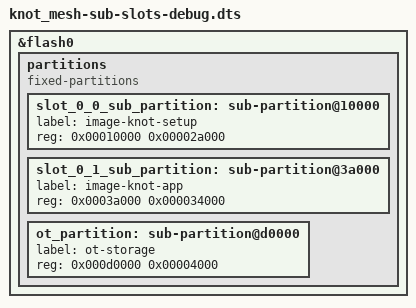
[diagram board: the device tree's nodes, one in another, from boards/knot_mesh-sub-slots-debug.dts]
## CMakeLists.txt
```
cmake_minimum_required(VERSION 3.8.2)
find_package(Git REQUIRED)

set(CONF_FILE
        "$ENV{KNOT_BASE}/core/core.conf \
         $ENV{KNOT_BASE}/core/overlay-knot-ot.conf \
         $ENV{KNOT_BASE}/core/boards/${BOARD}.conf \
         prj.conf"
)

if(NOT BOARD)
        error("Board not defined!")
endif ()

set(KCONFIG_ROOT $ENV{KNOT_BASE}/core/Kconfig)

if (NOT ${BOARD} STREQUAL qemu_x86)
        # Change dts with sub-partitions and use specific sub-partition to flash
        # Use special dts overlay in case of debugging
        if (KNOT_DEBUG)
                set(DTC_OVERLAY_MULTI_SLOT
                        $ENV{KNOT_BASE}/core/boards/${BOARD}-sub-slots-debug.dts
                )
        else()
                set(DTC_OVERLAY_MULTI_SLOT
                        $ENV{KNOT_BASE}/core/boards/${BOARD}-sub-slots-stock.dts
                )
        endif()
        set(DTC_OVERLAY_SET_SLOT
                $ENV{KNOT_BASE}/core/boards/overlay-main.dts
        )
        set(DTC_OVERLAY_FILE
                "${DTC_OVERLAY_FILE} ${DTC_OVERLAY_MULTI_SLOT} \
                 ${DTC_OVERLAY_SET_SLOT} ${DTC_OVERLAY_USER}"
        )
endif ()

include($ENV{ZEPHYR_BASE}/cmake/app/boilerplate.cmake NO_POLICY_SCOPE)

include(ExternalProject)

zephyr_get_include_directories_for_lang_as_string(C includes)
zephyr_get_system_include_directories_for_lang_as_string(C system_includes)
zephyr_get_compile_options_for_lang_as_string(C c_options)

set(PROTO_ROOT ${CMAKE_CURRENT_LIST_DIR}/build/external/proto)
set(PROTO_LIB_DIR ${PROTO_ROOT}/lib)
set(PROTO_INCLUDE_DIR ${PROTO_ROOT}/include)
set(PROTO_LIB knotprotocol)
if(EXTERNAL_PROJECT_PATH_KNOT_PROTOCOL)
        set(PROTO_SOURCE ${EXTERNAL_PROJECT_PATH_KNOT_PROTOCOL})
else()
        set(PROTO_GIT_REPO https://github.com/CESARBR/knot-protocol-source.git)
        set(PROTO_SOURCE ${PROTO_ROOT}/src/proto)
endif()

set(configure_flags
  "CC=${CMAKE_C_COMPILER}"
  "RANLIB=${CMAKE_RANLIB}"
  "CFLAGS=${c_options} ${includes} ${system_includes}"
  "LDFLAGS=-nostdlib"# Don't use the standard system startup files or libraries
  --host=${CROSS_COMPILE_TARGET}
  --target=${CROSS_COMPILE_TARGET}
  --prefix=${PROTO_ROOT}
)

add_library(${PROTO_LIB} STATIC IMPORTED GLOBAL)

set_target_properties(${PROTO_LIB} PROPERTIES IMPORTED_LOCATION
    ${PROTO_LIB_DIR}/lib${PROTO_LIB}.a
)

target_include_directories(app SYSTEM PRIVATE ${PROTO_INCLUDE_DIR})

target_link_libraries(app INTERFACE ${PROTO_LIB})

ExternalProject_Add(proto
    PREFIX ${PROTO_ROOT}
    BINARY_DIR ${PROTO_SOURCE}
    SOURCE_DIR ${PROTO_SOURCE}
    GIT_REPOSITORY ${PROTO_GIT_REPO}
    BUILD_BYPRODUCTS ${PROTO_LIB_DIR}/lib${PROTO_LIB}.a
    CONFIGURE_COMMAND ./bootstrap && ./configure ${configure_flags}

    COMMENT "bootstrapping..." # Text printed when step executes
    BUILD_COMMAND make
)

add_dependencies(proto syscall_list_h_target)
add_dependencies(proto syscall_macros_h_target)

add_dependencies(app proto)
if (NOT ${BOARD} STREQUAL qemu_x86)
        add_dependencies(app ot)
endif ()

FILE(GLOB core_sources $ENV{KNOT_BASE}/core/src/*.c)
target_sources(app PRIVATE ${core_sources})
target_include_directories(app PRIVATE $ENV{KNOT_BASE}/core/src)
```

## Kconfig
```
mainmenu "KNoT sample application"

menu "KNoT Thing"

config KNOT_NAME
	string "KNoT device name"
	default "knot"

config KNOT_THING_DATA_MAX
	int "Max number of KNoT items (sensors)"
	default 3

config KNOT_LOG
	bool "Enable KNoT log"
	default n
	help
	  This option enables log support for KNoT
	depends on LOG

choice
	prompt "KNoT log level"
	depends on KNOT_LOG
	help
	  This option selects KNoT log level.

config KNOT_LOG_LEVEL_ERROR
	bool "Error"
config KNOT_LOG_LEVEL_WARNING
	bool "Warning"
config KNOT_LOG_LEVEL_INFO
	bool "Info"
config KNOT_LOG_LEVEL_DEBUG
	bool "Debug"

endchoice

config KNOT_LOG_LEVEL
	int
	default 0 if !KNOT_LOG
	default 1 if KNOT_LOG_LEVEL_ERROR
	default 2 if KNOT_LOG_LEVEL_WARNING
	default 3 if KNOT_LOG_LEVEL_INFO
	default 4 if KNOT_LOG_LEVEL_DEBUG

endmenu

source "Kconfig.zephyr"
```

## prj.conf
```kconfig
# Generic networking options
CONFIG_NETWORKING=y
CONFIG_NET_TCP=y
CONFIG_NET_IPV6=y

# Kernel options
CONFIG_INIT_STACKS=y

# Logging
CONFIG_LOG=y
CONFIG_LOG_INPLACE_PROCESS=y


# Threading
CONFIG_NUM_PIPE_ASYNC_MSGS=2

# Network application options and configuration
CONFIG_NET_APP=y
CONFIG_NET_APP_CLIENT=y
CONFIG_NET_CONFIG_AUTO_INIT=y

CONFIG_NET_CONFIG_SETTINGS=y
CONFIG_NET_CONFIG_NEED_IPV6=y
CONFIG_NET_CONFIG_MY_IPV6_ADDR="2001:db8::1"
CONFIG_NET_CONFIG_PEER_IPV6_ADDR="2001:db8::2"
```

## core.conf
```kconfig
# Generic networking options
CONFIG_NETWORKING=y
CONFIG_NET_TCP=y
CONFIG_NET_UDP=n
CONFIG_NET_IPV6=y

# Kernel options
CONFIG_INIT_STACKS=y

# Threading
CONFIG_NUM_PIPE_ASYNC_MSGS=2

# Network application options and configuration
CONFIG_NET_SOCKETS=y
CONFIG_NET_CONFIG_AUTO_INIT=y

CONFIG_NET_CONFIG_SETTINGS=y
CONFIG_NET_CONFIG_NEED_IPV6=y
CONFIG_NET_CONFIG_MY_IPV6_ADDR="2001:db8::1"
CONFIG_NET_CONFIG_PEER_IPV6_ADDR="2001:db8::2"
```

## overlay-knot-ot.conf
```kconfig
CONFIG_CPLUSPLUS=y

# Disable IPv4
CONFIG_NET_IPV4=n

CONFIG_NET_IPV6=y
CONFIG_NET_IPV6_NBR_CACHE=n
CONFIG_NET_IPV6_MLD=n
CONFIG_NET_CONFIG_NEED_IPV6=y
CONFIG_NET_CONFIG_NEED_IPV4=n
CONFIG_NET_CONFIG_MY_IPV4_ADDR=""
CONFIG_NET_CONFIG_PEER_IPV4_ADDR=""

CONFIG_MAIN_STACK_SIZE=2048
CONFIG_SYSTEM_WORKQUEUE_STACK_SIZE=2048
CONFIG_NET_TX_STACK_SIZE=2048
CONFIG_NET_RX_STACK_SIZE=5120

# Disable conflicting IEEE802154 L2
CONFIG_NET_L2_IEEE802154=n
CONFIG_NET_L2_IEEE802154_SHELL=n
CONFIG_NET_DEBUG_L2_IEEE802154_FRAGMENT=n

CONFIG_NET_L2_OPENTHREAD=y

CONFIG_OPENTHREAD_DEBUG=y
CONFIG_OPENTHREAD_L2_DEBUG=y

# Openthread connection parameters
# Define invalid parameters to avoid starting a Thread network at system startup
CONFIG_OPENTHREAD_CHANNEL=0
CONFIG_OPENTHREAD_PANID=65535
CONFIG_OPENTHREAD_NETWORK_NAME=""
CONFIG_OPENTHREAD_XPANID=""
CONFIG_OPENTHREAD_MTD=y

# Thread by default registers quite a lot addresses.
CONFIG_NET_IF_UNICAST_IPV6_ADDR_COUNT=6
CONFIG_NET_IF_MCAST_IPV6_ADDR_COUNT=8

# Get OpenThread Settings from storage
CONFIG_SETTINGS_OT=y

# Set number of flash pages to be used by OpenThread
# It should be limited by the OT_STORAGE flash sub-partition size
CONFIG_OT_PLAT_FLASH_PAGES_COUNT=4
```

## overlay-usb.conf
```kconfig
# Enable shell without input options
CONFIG_SHELL=y
CONFIG_LOG_CMDS=n
CONFIG_SHELL_BACKSPACE_MODE_DELETE=n
CONFIG_SHELL_WILDCARD=n
CONFIG_SHELL_ECHO_STATUS=n
CONFIG_SHELL_METAKEYS=n
CONFIG_SHELL_HELP=n
CONFIG_SHELL_HELP_ON_WRONG_ARGUMENT_COUNT=n
CONFIG_SHELL_HISTORY=n
CONFIG_SHELL_STATS=n
CONFIG_SHELL_CMDS=n
CONFIG_SHELL_CMDS_RESIZE=n

# Enable UART Interruptions
CONFIG_UART_INTERRUPT_DRIVEN=y
CONFIG_UART_0_NRF_UARTE=y
CONFIG_UART_0_INTERRUPT_DRIVEN=y

# USB Stack
CONFIG_USB=y
CONFIG_USB_DEVICE_STACK=y
CONFIG_USB_CDC_ACM=y
CONFIG_USB_UART_CONSOLE=y
CONFIG_USB_MASS_STORAGE=n
CONFIG_USB_DEVICE_PRODUCT="KNoT Thing"

# Use LOG for printk messages
CONFIG_LOG_PRINTK=y

# Use console and shell for output
CONFIG_CONSOLE=y
CONFIG_STDOUT_CONSOLE=y
CONFIG_UART_SHELL_ON_DEV_NAME="CDC_ACM_0"
CONFIG_UART_CONSOLE=y
CONFIG_SERIAL=y
```

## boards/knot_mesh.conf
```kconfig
CONFIG_BT=n
CONFIG_BT_CTLR=n

CONFIG_GPIO=y

CONFIG_NET_TX_STACK_SIZE=4096
CONFIG_NET_RX_STACK_SIZE=5120

CONFIG_REBOOT=y

CONFIG_FLASH=y
CONFIG_FLASH_PAGE_LAYOUT=y
CONFIG_MPU_ALLOW_FLASH_WRITE=y

CONFIG_NET_TCP=y

CONFIG_IEEE802154_NRF5=y
CONFIG_IEEE802154_NRF5_DRV_NAME="IEEE802154_nrf5"
CONFIG_IEEE802154_NRF5_INIT_PRIO=80

CONFIG_TEST_RANDOM_GENERATOR=n
CONFIG_ENTROPY_NRF5_RNG=y

CONFIG_SYS_CLOCK_TICKS_PER_SEC=1000

CONFIG_FLOAT=y
CONFIG_FP_SHARING=y

# Flash kernel at choosen code partition
CONFIG_USE_CODE_PARTITION=y


# Settings
CONFIG_FLASH_MAP=y
CONFIG_SETTINGS=y
CONFIG_FCB=y
CONFIG_SETTINGS_FCB=y
CONFIG_SETTINGS_FCB_NUM_AREAS=4

# Disable UART to avoid conflicts with OpenThread
CONFIG_OPENTHREAD_SHELL=y
CONFIG_SHELL=y

# Disable shell inputs to better performance
CONFIG_LOG_CMDS=n
CONFIG_SHELL_BACKSPACE_MODE_DELETE=n
CONFIG_SHELL_WILDCARD=n
CONFIG_SHELL_ECHO_STATUS=n
CONFIG_SHELL_METAKEYS=n
CONFIG_SHELL_HELP=n
CONFIG_SHELL_HELP_ON_WRONG_ARGUMENT_COUNT=n
CONFIG_SHELL_HISTORY=n
CONFIG_SHELL_STATS=n
CONFIG_SHELL_CMDS=n
CONFIG_SHELL_CMDS_RESIZE=n

# Network buffers
CONFIG_NET_PKT_RX_COUNT=16
CONFIG_NET_PKT_TX_COUNT=16
CONFIG_NET_BUF_RX_COUNT=80
CONFIG_NET_BUF_TX_COUNT=80

# IP address options
CONFIG_NET_MAX_CONTEXTS=10

# USB
CONFIG_USB=y
CONFIG_USB_DEVICE_STACK=y
CONFIG_USB_CDC_ACM=y
CONFIG_USB_DEVICE_PRODUCT="KNoT Thing"
CONFIG_UART_SHELL_ON_DEV_NAME="CDC_ACM_0"
```

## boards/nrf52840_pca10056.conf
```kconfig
CONFIG_BT=n
CONFIG_BT_CTLR=n

CONFIG_GPIO=y

CONFIG_NET_TX_STACK_SIZE=4096
CONFIG_NET_RX_STACK_SIZE=5120

CONFIG_REBOOT=y

CONFIG_FLASH=y
CONFIG_FLASH_PAGE_LAYOUT=y
CONFIG_MPU_ALLOW_FLASH_WRITE=y

CONFIG_NET_TCP=y

CONFIG_IEEE802154_NRF5=y
CONFIG_IEEE802154_NRF5_DRV_NAME="IEEE802154_nrf5"
CONFIG_IEEE802154_NRF5_INIT_PRIO=80

CONFIG_TEST_RANDOM_GENERATOR=n
CONFIG_ENTROPY_NRF5_RNG=y

CONFIG_SYS_CLOCK_TICKS_PER_SEC=1000

CONFIG_FLOAT=y
CONFIG_FP_SHARING=y

# Flash kernel at choosen code partition
CONFIG_USE_CODE_PARTITION=y

# Settings
CONFIG_FLASH_MAP=y
CONFIG_SETTINGS=y
CONFIG_FCB=y
CONFIG_SETTINGS_FCB=y
CONFIG_SETTINGS_FCB_NUM_AREAS=8

# Shell
CONFIG_OPENTHREAD_SHELL=n
CONFIG_SHELL=n

# Network buffers
CONFIG_NET_PKT_RX_COUNT=16
CONFIG_NET_PKT_TX_COUNT=16
CONFIG_NET_BUF_RX_COUNT=80
CONFIG_NET_BUF_TX_COUNT=80

# IP address options
CONFIG_NET_MAX_CONTEXTS=10
```

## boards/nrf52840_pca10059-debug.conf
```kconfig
# Logging
CONFIG_LOG=y
CONFIG_LOG_PRINTK=y
CONFIG_LOG_IMMEDIATE=n

CONFIG_KNOT_LOG=y
CONFIG_KNOT_LOG_LEVEL_DEBUG=y

# USB
CONFIG_USB=y
CONFIG_USB_DEVICE_STACK=y
CONFIG_USB_CDC_ACM=y
CONFIG_USB_UART_CONSOLE=y
CONFIG_USB_DEVICE_PRODUCT="KNoT Thing"
CONFIG_USB_MASS_STORAGE=n

# Use console and shell for output
CONFIG_CONSOLE=y
CONFIG_STDOUT_CONSOLE=y

CONFIG_UART_CONSOLE=y
CONFIG_UART_SHELL_ON_DEV_NAME="CDC_ACM_0"

CONFIG_SERIAL=y

# Disable shell input options
CONFIG_LOG_CMDS=n
CONFIG_SHELL=y
CONFIG_SHELL_BACKSPACE_MODE_DELETE=n
CONFIG_SHELL_WILDCARD=n
CONFIG_SHELL_ECHO_STATUS=n
CONFIG_SHELL_METAKEYS=n
CONFIG_SHELL_HELP=n
CONFIG_SHELL_HELP_ON_WRONG_ARGUMENT_COUNT=n
CONFIG_SHELL_HISTORY=n
CONFIG_SHELL_STATS=n
CONFIG_SHELL_CMDS=n
CONFIG_SHELL_CMDS_RESIZE=n
CONFIG_SHELL_BACKEND_SERIAL_INTERRUPT_DRIVEN=n
```

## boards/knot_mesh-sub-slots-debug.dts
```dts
/*
 * Overlay file to permit using sub-slots with extend space for setup app.
 * This file is meant for apps on debug mode, not stock mode.
 */
&flash0 {
	/*
	 * For more information, see:
	 * http://docs.zephyrproject.org/latest/devices/dts/flash_partitions.html
	 */
	partitions {
		compatible = "fixed-partitions";
		#address-cells = <1>;
		#size-cells = <1>;

		/*
		 * Hack: Split image-0 into two sub-images
		 * (knot-setup and knot-app) so they can be refer to each other
		 * and recognized by MCUBOOT as a single image.
		 */

		slot_0_0_sub_partition: sub-partition@10000 {
			label = "image-knot-setup";
			reg = <0x00010000 0x00002a000>;
		};

		slot_0_1_sub_partition: sub-partition@3a000 {
			label = "image-knot-app";
			reg = <0x0003a000 0x000034000>;
		};

		/*
		 * Using first 4 pages of scratch partition for
		 * OpenThread storage.
		 * This is allowed as the scratch area is used only
		 * during OTA update.
		 */
		ot_partition: sub-partition@d0000 {
			label = "ot-storage";
			reg = <0x000d0000 0x00004000>;
		};
	};
};
```

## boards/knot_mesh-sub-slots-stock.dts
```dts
/*
 * Overlay file to permit using sub-slots with reduced space for setup app.
 */
&flash0 {
	/*
	 * For more information, see:
	 * http://docs.zephyrproject.org/latest/devices/dts/flash_partitions.html
	 */
	partitions {
		compatible = "fixed-partitions";
		#address-cells = <1>;
		#size-cells = <1>;

		/*
		 * Hack: Split image-0 into two sub-images
		 * (knot-setup and knot-app) so they can be refer to each other
		 * and recognized by MCUBOOT as a single image.
		 */

		slot_0_0_sub_partition: sub-partition@10000 {
			label = "image-knot-setup";
			reg = <0x00010000 0x00001c000>;
		};

		slot_0_1_sub_partition: sub-partition@2c000 {
			label = "image-knot-app";
			reg = <0x0002c000 0x000042000>;
		};

		/*
		 * Using first 4 pages of scratch partition for
		 * OpenThread storage.
		 * This is allowed as scratch area is used only
		 * during OTA update.
		 */
		ot_partition: sub-partition@d0000 {
			label = "ot-storage";
			reg = <0x000d0000 0x00004000>;
		};
		/* Nordic nRF5 bootloader <0xe0000 0x1c000>
		 *
		 * In addition, the last and second last flash pages
		 * are used by the nRF5 bootloader and MBR to store settings.
		 */
	};
};
```

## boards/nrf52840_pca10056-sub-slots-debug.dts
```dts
/*
 * Overlay file to permit using sub-slots with extend space for setup app.
 * This file is meant for apps on debug mode, not stock mode.
 */
&flash0 {
	/*
	 * For more information, see:
	 * http://docs.zephyrproject.org/latest/devices/dts/flash_partitions.html
	 */
	partitions {
		compatible = "fixed-partitions";
		#address-cells = <1>;
		#size-cells = <1>;

		/*
		 * Hack: Split image-0 into two sub-images
		 * (knot-setup and knot-app) so they can be refer to each other
		 * and recognized by MCUBOOT as a single image.
		 */

		slot_0_0_sub_partition: sub-partition@c000 {
			label = "image-knot-setup";
			reg = <0x0000C000 0x000030000>;
		};

		slot_0_1_sub_partition: sub-partition@3c000 {
			label = "image-knot-app";
			reg = <0x0003C000 0x000037000>;
		};

		/*
		 * Using last 4 pages of storage partition
		 */

		ot_partition: partition@fe000 {
			label = "ot-storage";
			reg = <0x000fc000 0x00004000>;
		};
	};
};
```

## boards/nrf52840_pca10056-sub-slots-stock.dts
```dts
/*
 * Overlay file to permit using sub-slots with reduced space for setup app.
 */
&flash0 {
	/*
	 * For more information, see:
	 * http://docs.zephyrproject.org/latest/devices/dts/flash_partitions.html
	 */
	partitions {
		compatible = "fixed-partitions";
		#address-cells = <1>;
		#size-cells = <1>;

		/*
		 * Hack: Split image-0 into two sub-images
		 * (knot-setup and knot-app) so they can be refer to each other
		 * and recognized by MCUBOOT as a single image.
		 */

		slot_0_0_sub_partition: sub-partition@c000 {
			label = "image-knot-setup";
			reg = <0x0000c000 0x00001c000>;
		};

		slot_0_1_sub_partition: sub-partition@28000 {
			label = "image-knot-app";
			reg = <0x00028000 0x00004b000>;
		};

		/*
		 * Using first 4 pages of scratch partition for
		 * OpenThread storage.
		 * This is allowed as scratch area is used only
		 * during OTA update.
		 */
		ot_partition: sub-partition@da000 {
			label = "ot-storage";
			reg = <0x000da000 0x00004000>;
		};
	};
};
```

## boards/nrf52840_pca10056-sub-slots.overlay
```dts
&flash0 {
	/*
	 * For more information, see:
	 * http://docs.zephyrproject.org/latest/devices/dts/flash_partitions.html
	 */
	partitions {
		compatible = "fixed-partitions";
		#address-cells = <1>;
		#size-cells = <1>;

		/*
		 * Hack: Split image-0 into two sub-images
		 * (knot-setup and knot-app) so they can be refer to each other
		 * and recognized by MCUBOOT as a single image.
		 */

		slot_0_0_sub_partition: sub-partition@c000 {
			label = "image-knot-setup";
			reg = <0x0000C000 0x000020000>;
		};

		slot_0_1_sub_partition: sub-partition@2c000 {
			label = "image-knot-app";
			reg = <0x0002C000 0x000047000>;
		};

		/*
		 * Using last 4 pages of storage partition
		 */

		ot_partition: partition@fe000 {
			label = "ot-storage";
			reg = <0x000fc000 0x00004000>;
		};
	};
};
```

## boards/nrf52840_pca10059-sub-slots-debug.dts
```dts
/*
 * Overlay file to permit using sub-slots with extend space for setup app.
 * This file is meant for apps on debug mode, not stock mode.
 */
&flash0 {
	/*
	 * For more information, see:
	 * http://docs.zephyrproject.org/latest/devices/dts/flash_partitions.html
	 */
	partitions {
		compatible = "fixed-partitions";
		#address-cells = <1>;
		#size-cells = <1>;

		/*
		 * Hack: Split image-0 into two sub-images
		 * (knot-setup and knot-app) so they can be refer to each other
		 * and recognized by MCUBOOT as a single image.
		 */

		slot_0_0_sub_partition: sub-partition@10000 {
			label = "image-knot-setup";
			reg = <0x00010000 0x00002a000>;
		};

		slot_0_1_sub_partition: sub-partition@3a000 {
			label = "image-knot-app";
			reg = <0x0003a000 0x000034000>;
		};

		/*
		 * Using last 2 pages of storage partition
		 */
		ot_partition: partition@fe000 {
			label = "ot-storage";
			reg = <0x000ce000 0x00002000>;
		};
	};
};
```

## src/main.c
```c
/* main.c - KNoT Application Client */

/*
 * Copyright (c) 2018, CESAR. All rights reserved.
 *
 * SPDX-License-Identifier: Apache-2.0
 */

/*
 * The knot client application is acting as a client that is run in Zephyr OS,
 * The client sends sensor data encapsulated using KNoT protocol.
 */

#include <zephyr.h>
#include <net/net_core.h>
#include <logging/log.h>
#include <settings/settings.h>
#if CONFIG_SETTINGS_OT
	#include <settings/settings_ot.h>
#endif

#include "proto.h"
#include "net.h"
#include "storage.h"

LOG_MODULE_REGISTER(knot, CONFIG_KNOT_LOG_LEVEL);
K_PIPE_DEFINE(p2n_pipe, 128, 4);
K_PIPE_DEFINE(n2p_pipe, 128, 4);
static struct k_sem quit_lock;

void main(void)
{
	int ret;

	LOG_DBG("*** Welcome to KNoT! %s\n", CONFIG_ARCH);

	k_sem_init(&quit_lock, 0, UINT_MAX);

	/* Guarantees NET and PROTO threads will be created */
	k_sched_lock();

	/* Initializing KNoT storage */
	LOG_DBG("Initializing storage module");
	ret = storage_init();
	if (ret)
		LOG_ERR("KNoT Storage init failed!");

	#if CONFIG_SETTINGS_OT
		/* Initializing OpenThread settings */
		LOG_DBG("Initializing OpenThread settings");
		ret = settings_ot_init();
		if (ret)
			LOG_ERR("OpenThread settings init failed!");

	#endif

	#if CONFIG_SETTINGS
		LOG_DBG("Loading stored values");
		ret = settings_load();
		if (ret)
			LOG_ERR("Settings load failed (err %d)", ret);
	#endif

	/*
	 * KNoT state thread: manage device registration, detects
	 * sensor data changes acting like a proxy forwarding data
	 * from sensors to network layer (and oposite). Proto is
	 * consumer of ipdu fifo and producer of opdu.
	 */
	if (proto_start(&p2n_pipe, &n2p_pipe) < 0)
		return;

	/*
	 * Network thread: manage traffic from TCP or non-ip wireless
	 * technologies. Each technology(thread) is responsible for
	 * managing incoming and outgoing data. Net is consumer of
	 * opdu fifo and producer of ipdu.
	 */
	if (net_start(&p2n_pipe, &n2p_pipe) < 0)
		return;

	/* Allows NET and PROTO thread scheduling */
	k_sched_unlock();

	k_sem_take(&quit_lock, K_FOREVER);

	net_stop();
	proto_stop();
}
```

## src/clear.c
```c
/*
 * Copyright (c) 2019, CESAR. All rights reserved.
 *
 * SPDX-License-Identifier: Apache-2.0
 */

#if !CONFIG_BOARD_QEMU_X86
#include <zephyr.h>
#include <settings/settings_ot.h>
#include <logging/log.h>
#include <flash.h>

#include "storage.h"
#include "clear.h"

LOG_MODULE_REGISTER(knot_clear, CONFIG_KNOT_LOG_LEVEL);

int clear_ot_nvs(void)
{
	struct device *flash_dev;
	int rc;

	flash_dev = device_get_binding(DT_FLASH_DEV_NAME);
	if (!flash_dev) {
		LOG_ERR("Flash driver was not found!");
		return -1;
	}

	/* Erase OpenThread flash partition */
	flash_write_protection_set(flash_dev, false);
	rc = flash_erase(flash_dev,
			 DT_FLASH_AREA_OT_STORAGE_OFFSET,
			 DT_FLASH_AREA_OT_STORAGE_SIZE);
	if (rc)
		LOG_ERR("Failed to clear OpenThread's NVS");

	flash_write_protection_set(flash_dev, true);

	return rc;
}

static int clear_settings(void)
{
	struct device *flash_dev;
	int rc;

	flash_dev = device_get_binding(DT_FLASH_DEV_NAME);
	if (!flash_dev) {
		LOG_ERR("Flash driver was not found!");
		return -1;
	}

	/* Erase Storage flash partition */
	flash_write_protection_set(flash_dev, false);
	rc = flash_erase(flash_dev,
			 DT_FLASH_AREA_STORAGE_OFFSET,
			 DT_FLASH_AREA_STORAGE_SIZE);
	if (rc)
		LOG_ERR("Failed to clear Storage flash partition");

	flash_write_protection_set(flash_dev, true);

	return rc;
}

int clear_factory(void)
{
	int rc;
	int ret = 0;

	rc = storage_reset();
	if (rc)
		ret = -1;

	rc = settings_ot_reset();
	if (rc)
		ret = -1;

	rc = clear_ot_nvs();
	if (rc)
		ret = -1;

	rc = clear_settings();
	if (rc)
		ret = -1;

	return ret;
}
#endif
```

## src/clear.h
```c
/*
 * Copyright (c) 2019, CESAR. All rights reserved.
 *
 * SPDX-License-Identifier: Apache-2.0
 */

int clear_ot_nvs(void);

int clear_factory(void);
```

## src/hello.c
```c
/* net.c - KNoT Application Client */

/*
 * Copyright (c) 2018, CESAR. All rights reserved.
 *
 * SPDX-License-Identifier: Apache-2.0
 */

/*
 * The knot client application is acting as a client that is run in Zephyr OS,
 * The client sends sensor data encapsulated using KNoT netcol.
 */


#include <zephyr.h>
#include <net/net_core.h>
#include <logging/log.h>

#include "knot.h"
#include "knot_types.h"
#include "knot_protocol.h"

LOG_MODULE_DECLARE(knot, LOG_LEVEL_DBG);

/* Tracked values */
static int thermo = 0;
static int high_temp = 100000;
static bool led = true;
static char plate[] = "BRZ0000";
static int plate_upper = 99999;

/*
 * Use GPIO only for real boards.
 * Use timer to mock values change if using qemu.
 */
#if CONFIG_BOARD_NRF52840_PCA10056
#include <device.h>
#include <board.h>
#include <gpio.h>
#define GPIO_PORT		SW0_GPIO_NAME /* General GPIO Controller */
#define BUTTON_PIN		SW0_GPIO_PIN /* User button */
#define LED_PIN			LED0_GPIO_PIN /* User button */

static struct device *gpiob;		/* GPIO device */
static struct gpio_callback button_cb; /* Button pressed callback */

static void btn_press(struct device *gpiob,
		       struct gpio_callback *cb, u32_t pins)
{
	led = !led;
	gpio_pin_write(gpiob, LED_PIN, !led); /* Update GPIO */

}
#elif CONFIG_BOARD_QEMU_X86

#define UPDATE_PERIOD K_SECONDS(3) /* Update values each 3 seconds */
static void val_update(struct k_timer *timer_id)
{
	led = !led;
	k_timer_start(timer_id, UPDATE_PERIOD, UPDATE_PERIOD);
}
K_TIMER_DEFINE(val_update_timer, val_update, NULL);
#endif

static void changed_thermo(struct knot_proxy *proxy)
{
	u8_t id;

	id = knot_proxy_get_id(proxy);
	knot_proxy_value_get_basic(proxy, &thermo);

	LOG_INF("Value for thermo with id %u changed to %d", id, thermo);
}

static void poll_thermo(struct knot_proxy *proxy)
{
	u8_t id;
	bool res;

	id = knot_proxy_get_id(proxy);
	/* Get current temperature from actual object */
	thermo++;

	/* Pushing temperature to remote */
	res = knot_proxy_value_set_basic(proxy, &thermo);

	/* Notify if sent */
	if (res)
		LOG_INF("Sending value %d for thermo with id %u", thermo, id);

}

static void changed_led(struct knot_proxy *proxy)
{
	knot_proxy_value_get_basic(proxy, &led);
	LOG_INF("Value for led changed to %d", led);

#if CONFIG_BOARD_NRF52840_PCA10056
	gpio_pin_write(gpiob, LED_PIN, !led); /* Led is On at LOW */
#endif
}

static void poll_led(struct knot_proxy *proxy)
{
	/* Pushing status to remote */
	bool res;
	res = knot_proxy_value_set_basic(proxy, &led);

	/* Notify if sent */
	if (res) {
		if (led)
			LOG_INF("Sending value true for led");
		else
			LOG_INF("Sending value false for led");
	}
}

static void plate_changed(struct knot_proxy *proxy)
{
	int len;

	if (knot_proxy_value_get_string(proxy, plate, sizeof(plate), &len))
		LOG_INF("Plate changed %s", plate);
}

static void random_plate(struct knot_proxy *proxy)
{
	u8_t id;
	int num;
	bool res;
	id = knot_proxy_get_id(proxy);

	num = (sys_rand32_get() % 7);
	plate[3] = '0' + num;
	plate[4] = '1' + num;
	plate[5] = '2' + num;
	plate[6] = '3' + num;

	res = knot_proxy_value_set_string(proxy, plate, sizeof(plate));

	/* Notify if sent */
	if (res)
		LOG_INF("Sent plate %s", plate);
}

void setup(void)
{
	bool success;

	/* THERMO - Sent every 5 seconds or at high temperatures */
	if (knot_proxy_register(0, "THERMO", KNOT_TYPE_ID_TEMPERATURE,
		      KNOT_VALUE_TYPE_INT, KNOT_UNIT_TEMPERATURE_C,
		      changed_thermo, poll_thermo) == NULL) {
		LOG_ERR("THERMO_0 failed to register");
	}
	success = knot_proxy_set_config(0,
					KNOT_EVT_FLAG_TIME, 5,
					KNOT_EVT_FLAG_UPPER_THRESHOLD,
					high_temp, NULL);
	if (!success)
		LOG_ERR("THERMO failed to configure");

	/* BUTTON - Sent after change */
	if (knot_proxy_register(1, "LED", KNOT_TYPE_ID_SWITCH,
		      KNOT_VALUE_TYPE_BOOL, KNOT_UNIT_NOT_APPLICABLE,
		      changed_led, poll_led) == NULL) {
		LOG_ERR("LED failed to register");
	}
	success = knot_proxy_set_config(1, KNOT_EVT_FLAG_CHANGE, NULL);
	if (!success)
		LOG_ERR("LED failed to configure");

	/* PLATE - Will fail to configure */
	if (knot_proxy_register(2, "PLATE", KNOT_TYPE_ID_NONE,
		      KNOT_VALUE_TYPE_RAW, KNOT_UNIT_NOT_APPLICABLE,
		      plate_changed, random_plate) == NULL) {
		LOG_ERR("PLATE failed to register");
	}
	/* Limit flag added for raw type variable for testing purposes */
	success = knot_proxy_set_config(2,
				   KNOT_EVT_FLAG_TIME, 2,
				   KNOT_EVT_FLAG_UPPER_THRESHOLD, plate_upper,
				   NULL);
	if (!success)
		LOG_ERR("PLATE failed to configure");

	/* Peripherals control */
#if CONFIG_BOARD_NRF52840_PCA10056
	/* Read button */
	gpiob = device_get_binding(GPIO_PORT);
	/* Button Pin has pull up, interruption on low edge and debounce */
	gpio_pin_configure(gpiob, BUTTON_PIN,
			   GPIO_DIR_IN | GPIO_PUD_PULL_UP | GPIO_INT_DEBOUNCE |
			   GPIO_INT | GPIO_INT_EDGE | GPIO_INT_ACTIVE_LOW);
	gpio_init_callback(&button_cb, btn_press, BIT(BUTTON_PIN));
	gpio_add_callback(gpiob, &button_cb);
	gpio_pin_enable_callback(gpiob, BUTTON_PIN);

	/* Led pin */
	gpio_pin_configure(gpiob, LED_PIN, GPIO_DIR_OUT);

#elif CONFIG_BOARD_QEMU_X86
	k_timer_start(&val_update_timer, UPDATE_PERIOD, UPDATE_PERIOD);
#endif

}

void loop(void)
{
}
```

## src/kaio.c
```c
/*
 * Copyright (c) 2018, CESAR. All rights reserved.
 *
 * SPDX-License-Identifier: Apache-2.0
 */

#include <zephyr.h>

#include <string.h>

#include "knot_protocol.h"
#include "knot_types.h"
#include "msg.h"
#include "kaio.h"
#include "knot.h"

#define MIN(a, b)         (((a) < (b)) ? (a) : (b))

#define check_int_change(io, value)	\
	(KNOT_EVT_FLAG_CHANGE & io->config.event_flags \
	&& value != io->value.val_i.value)

#define check_int_up_limit(io, value)	\
	(KNOT_EVT_FLAG_UPPER_THRESHOLD & io->config.event_flags \
	&& value > io->value.val_i.value)

#define check_int_low_limit(io, value)	\
	(KNOT_EVT_FLAG_LOWER_THRESHOLD & io->config.event_flags \
	&& value < io->value.val_i.value)


static struct aio {
	/* KNoT identifier */
	u8_t			id;

	/* Schema values */
	knot_schema		schema;

	/* Data values */
	bool			send;
	knot_value_type		value;
	u8_t			len;

	/* Config values */
	knot_config		config;

	/* Time values */
	u32_t			last_timeout;

	knot_callback_t		read_cb;
	knot_callback_t		write_cb;
} aio[KNOT_THING_DATA_MAX];

static u8_t last_id = 0xff;

void kaio_start(void)
{
	int index;

	memset(aio, 0, sizeof(aio));

	for (index = 0; (index < sizeof(aio) / sizeof(struct aio)); index++)
		aio[index].id = 0xff;
}

void kaio_stop(void)
{

}

s8_t knot_register(u8_t id, const char *name,
		   u16_t type_id, u8_t value_type, u8_t unit,
		   knot_callback_t read_cb, knot_callback_t write_cb)
{
	struct aio *io;

	/* Out of index? */
	if (id >= KNOT_THING_DATA_MAX)
		return -EINVAL;

	/* Assigned already? */
	if (aio[id].id != 0xff)
		return -EACCES;

	/* Basic field validation */
	if (knot_schema_is_valid(type_id, value_type, unit) != 0 || !name)
		return -EINVAL;

	io = &aio[id];

	io->id = id;
	io->schema.type_id = type_id;
	io->schema.unit = unit;
	io->schema.value_type = value_type;
	io->send = true;
	io->len = 0;

	strncpy(io->schema.name, name,
		MIN(KNOT_PROTOCOL_DATA_NAME_LEN, strlen(name)));

	/* Set default config */
	io->config.event_flags = KNOT_EVT_FLAG_TIME;
	io->config.time_sec = 30;

	io->read_cb = read_cb;
	io->write_cb = write_cb;

	if (id > last_id || last_id == 0xff)
		last_id = id;

	return 0;
}

const knot_schema *kaio_get_schema(u8_t id)
{
	if (aio[id].id == 0xff)
		return NULL;

	return &(aio[id].schema);
}

u8_t kaio_get_last_id(void)
{
	return last_id;
}

s8_t kaio_read(u8_t id, knot_value_type *value)
{
	struct aio *io;

	if (aio[id].id == 0xff)
		return -EINVAL;

	io = &aio[id];

	if (io->read_cb == NULL)
		return 0;

	io->len = 0;

	io->read_cb(id);

	/*
	 * Read callback may set new values. When a
	 * new value is set "len" field is set.
	 */
	return io->len;
}

s8_t kaio_write(u8_t id, knot_value_type *value)
{
	struct aio *io;

	if (aio[id].id == 0xff)
		return -EINVAL;

	io = &aio[id];

	if (io->write_cb == NULL)
		return 0;

	memcpy(&io->value, value, sizeof(*value));

	/*
	 * New values sent from cloud are informed to
	 * the user app through write callback.
	 */

	io->write_cb(id);

	return io->len;
}

s8_t kaio_force_send(u8_t id)
{
	struct aio *io;

	if (aio[id].id == 0xff)
		return -EINVAL;

	io = &aio[id];

	io->send = true;

	return 0;
}

static s8_t kaio_set_value(u8_t id, knot_value_type *value)
{
	/* TODO: Split this function */
	struct aio *io;

	if (aio[id].id == 0xff)
		return -EINVAL;

	io = &aio[id];

	switch (io->schema.value_type) {
	case KNOT_VALUE_TYPE_FLOAT:
		/* TODO: Include decimal float part to comparison */
		if (KNOT_EVT_FLAG_CHANGE & io->config.event_flags
				&& value->val_f.value_int
				!= io->value.val_f.value_int)
			io->send = true;

		if (KNOT_EVT_FLAG_UPPER_THRESHOLD & io->config.event_flags
				&& value->val_f.value_int
				> io->value.val_f.value_int)
			io->send = true;

		if (KNOT_EVT_FLAG_LOWER_THRESHOLD & io->config.event_flags
				&& value->val_f.value_int
				< io->value.val_f.value_int)
			io->send = true;
		break;
	case KNOT_VALUE_TYPE_BOOL:
		if (KNOT_EVT_FLAG_CHANGE & io->config.event_flags
				&& value->val_b != io->value.val_b)
			io->send = true;
		break;
	case KNOT_VALUE_TYPE_RAW:
		/* TODO: Deal with raw size */
		if (KNOT_EVT_FLAG_CHANGE & io->config.event_flags
				&& !strcmp(value->raw, io->value.raw))
			io->send = true;
		break;
	default:
		return -1;
	}

	if (io->send == true)
		memcpy(value, &io->value, sizeof(*value));

	return 0;
}

static s8_t kaio_get_value(u8_t id, knot_value_type *value)
{
	struct aio *io;

	if (aio[id].id == 0xff)
		return -EINVAL;

	io = &aio[id];

	memcpy(&io->value, value, sizeof(*value));

	return sizeof(*value);
}

static bool check_timeout(u8_t id)
{
	u32_t current_time, elapsed_time;
	struct aio *io;

	io = &aio[id];

	if (!(KNOT_EVT_FLAG_TIME & io->config.event_flags))
		return false;

	current_time = k_uptime_get();
	elapsed_time = current_time - io->last_timeout;
	if (elapsed_time >= (io->config.time_sec * 1000)) {
		io->last_timeout = current_time;
		return true;
	}
	return false;
}

/* TODO: Set bool data */

void knot_set_int(u8_t id, const int value)
{
	struct aio *io;

	io = &aio[id];

	if (io->id == 0xff || io->schema.value_type != KNOT_VALUE_TYPE_INT)
		return;

	/* Checking if should send data or not*/
	if ( (io->send == true) ||
	     check_timeout(id) ||
	     check_int_change(io, value) ||
	     check_int_up_limit(io, value) ||
	     check_int_low_limit(io, value) )
	{
		io->send = true;
		io->len = sizeof(int);
		io->value.val_i.value = value;
	}
	return;
}

/* TODO: Set float data */

/* TODO: Set raw data */

s8_t knot_get_int(u8_t id, int *value)
{
	if (aio[id].id == 0xff)
		return -EINVAL;

	*value = (int) aio[id].value.val_i.value;
	return sizeof(int);
}
```

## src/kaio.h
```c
/*
 * Copyright (c) 2018, CESAR. All rights reserved.
 *
 * SPDX-License-Identifier: Apache-2.0
 */
```

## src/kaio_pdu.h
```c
/*
 * Copyright (c) 2018, CESAR. All rights reserved.
 *
 * SPDX-License-Identifier: Apache-2.0
 */

s8_t kaio_pdu_create_schema(u8_t id, knot_msg_schema *msg);
```

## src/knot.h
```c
/*
 * Copyright (c) 2018, CESAR. All rights reserved.
 *
 * SPDX-License-Identifier: Apache-2.0
 */

/*
 * Similar to Arduino:
 * setup() is called once and loop() is always called at idle state.
 * Sensors and actuactors should be registered at setup() function
 * definition and loop() must NOT be blooking.
 *
 * setup() and loop() must be defined at user app context.
 */
void setup(void);
void loop(void);

/* Proxy: Virtual representation of the remote device */
struct knot_proxy;

typedef void (*knot_callback_t) (struct knot_proxy *proxy);

/* Set knot to track and update data items */
int knot_data_register(u8_t id, const char *name,
		       u16_t type_id, u8_t value_type, u8_t unit,
		       void *target, size_t target_len,
		       knot_callback_t write_cb, knot_callback_t read_cb);

/*
 * This fuction configures which events should send proxy value to cloud
 *
 * @param id Sensor ID.
 * @param ... Optional list of event flags.
 *
 * This function must end with NULL
 */
bool knot_data_config(u8_t id, ...);

/* Proxy properties */
u8_t knot_proxy_get_id(struct knot_proxy *proxy);

/* Proxy helpers to get or set sensor data at the remote */
bool knot_proxy_value_set_basic(struct knot_proxy *proxy,
				const void *value);
bool knot_proxy_value_set_string(struct knot_proxy *proxy,
				 const char *value, int len);

bool knot_proxy_value_get_basic(struct knot_proxy *proxy,
				void *value);
bool knot_proxy_value_get_string(struct knot_proxy *proxy,
				 char *value, int len, int *olen);
```

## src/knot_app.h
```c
/* knot_app.h - KNoT Application Client */

/*
 * Copyright (c) 2018, CESAR. All rights reserved.
 *
 * SPDX-License-Identifier: Apache-2.0
 */

/*
 * Similar to Arduino:
 * setup() is called once and loop() is always called at idle state.
 * Sensors and actuactors should be registered at setup() function
 * definition and loop() must NOT be blooking.
 */
void setup(void);
void loop(void);
```

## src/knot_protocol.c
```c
/*
 * Copyright (c) 2016, CESAR.
 * All rights reserved.
 *
 * This software may be modified and distributed under the terms
 * of the BSD license. See the LICENSE file for details.
 *
 */

#include <stdint.h>
#include <errno.h>

#include "knot_types.h"
#include "knot_protocol.h"

/* Bitmask to identify used unit */
#define UNIT_MASK(unit)		(1 << (unit))

#define UNIT_VOLTAGE_MASK	(UNIT_MASK(KNOT_UNIT_VOLTAGE_V) |		\
					UNIT_MASK(KNOT_UNIT_VOLTAGE_MV) |	\
					UNIT_MASK(KNOT_UNIT_VOLTAGE_KV))

#define UNIT_CURRENT_MASK	(UNIT_MASK(KNOT_UNIT_CURRENT_A) |		\
					UNIT_MASK(KNOT_UNIT_CURRENT_MA))

#define UNIT_RESISTENCE_MASK	(UNIT_MASK(KNOT_UNIT_RESISTENCE_OHM))

#define UNIT_POWER_MASK		(UNIT_MASK(KNOT_UNIT_POWER_W) |			\
					UNIT_MASK( KNOT_UNIT_POWER_KW) |	\
					UNIT_MASK(KNOT_UNIT_POWER_MW))

#define UNIT_TEMP_MASK		(UNIT_MASK(KNOT_UNIT_TEMPERATURE_C) |		\
					UNIT_MASK(KNOT_UNIT_TEMPERATURE_F) |	\
					UNIT_MASK(KNOT_UNIT_TEMPERATURE_K))

#define UNIT_HUM_MASK		(UNIT_MASK(KNOT_UNIT_RELATIVE_HUMIDITY))

#define UNIT_LUM_MASK		(UNIT_MASK(KNOT_UNIT_LUMINOSITY_LM) |		\
					UNIT_MASK(KNOT_UNIT_LUMINOSITY_CD) |	\
					UNIT_MASK(KNOT_UNIT_LUMINOSITY_LX))

#define UNIT_TIME_MASK		(UNIT_MASK(KNOT_UNIT_TIME_S) |			\
					UNIT_MASK(KNOT_UNIT_TIME_MS) |		\
					UNIT_MASK(KNOT_UNIT_TIME_US))

#define UNIT_MASS_MASK		(UNIT_MASK(KNOT_UNIT_MASS_KG) |			\
					UNIT_MASK(KNOT_UNIT_MASS_G) |		\
					UNIT_MASK(KNOT_UNIT_MASS_LB) |		\
					UNIT_MASK(KNOT_UNIT_MASS_OZ))

#define UNIT_PRESSURE_MASK	(UNIT_MASK(KNOT_UNIT_PRESSURE_PA) |		\
					UNIT_MASK(KNOT_UNIT_PRESSURE_PSI) |	\
					UNIT_MASK(KNOT_UNIT_PRESSURE_BAR))

#define UNIT_DISTANCE_MASK	(UNIT_MASK(KNOT_UNIT_DISTANCE_M) |		\
					 UNIT_MASK(KNOT_UNIT_DISTANCE_CM) |	\
					 UNIT_MASK(KNOT_UNIT_DISTANCE_MI) |	\
					 UNIT_MASK(KNOT_UNIT_DISTANCE_IN))

#define UNIT_ANGLE_MASK		(UNIT_MASK(KNOT_UNIT_ANGLE_RAD) |		\
					 UNIT_MASK(KNOT_UNIT_ANGLE_DEGREE))

#define UNIT_VOL_MASK		(UNIT_MASK(KNOT_UNIT_VOLUME_L) |		\
					UNIT_MASK(KNOT_UNIT_VOLUME_ML) |	\
					UNIT_MASK(KNOT_UNIT_VOLUME_FLOZ) |	\
					UNIT_MASK(KNOT_UNIT_VOLUME_GAL))

#define UNIT_AREA_MASK		(UNIT_MASK(KNOT_UNIT_AREA_M2) |			\
					UNIT_MASK(KNOT_UNIT_AREA_HA) |		\
					UNIT_MASK(KNOT_UNIT_AREA_AC))

#define UNIT_RAIN_MASK		(UNIT_MASK(KNOT_UNIT_RAIN_MM))

#define UNIT_DENSITY_MASK	(UNIT_MASK(KNOT_UNIT_DENSITY_KGM3))

#define UNIT_LAT_MASK		(UNIT_MASK(KNOT_UNIT_LATITUDE_DEGREE))

#define UNIT_LONG_MASK		(UNIT_MASK(KNOT_UNIT_LONGITUDE_DEGREE))

#define UNIT_SPEED_MASK		(UNIT_MASK(KNOT_UNIT_SPEED_MS) |		\
					 UNIT_MASK(KNOT_UNIT_SPEED_CMS) |	\
					 UNIT_MASK(KNOT_UNIT_SPEED_KMH) |	\
					 UNIT_MASK(KNOT_UNIT_SPEED_MIH))

#define UNIT_VOLFLOW_MASK	(UNIT_MASK(KNOT_UNIT_VOLUMEFLOW_M3S) |		\
					UNIT_MASK(KNOT_UNIT_VOLUMEFLOW_SCMM) |	\
					UNIT_MASK(KNOT_UNIT_VOLUMEFLOW_LS) |	\
					UNIT_MASK(KNOT_UNIT_VOLUMEFLOW_LM) |	\
					UNIT_MASK(KNOT_UNIT_VOLUMEFLOW_FT3S) |	\
					UNIT_MASK(KNOT_UNIT_VOLUMEFLOW_GALM))

#define UNIT_ENERGY_MASK	(UNIT_MASK(KNOT_UNIT_ENERGY_J) |		\
					UNIT_MASK(KNOT_UNIT_ENERGY_NM) |	\
					UNIT_MASK(KNOT_UNIT_ENERGY_WH) |	\
					UNIT_MASK(KNOT_UNIT_ENERGY_KWH) |	\
					UNIT_MASK(KNOT_UNIT_ENERGY_CAL) |	\
					UNIT_MASK(KNOT_UNIT_ENERGY_KCAL))

#define TYPE_ID_MASK(type)	(type & 0x000F)

static const struct schema {
	uint8_t		value_type;
	uint32_t	unit_mask;
} basic_types[]  = {
	{KNOT_VALUE_TYPE_RAW, 0xFFFF			},
	{KNOT_VALUE_TYPE_INT, UNIT_VOLTAGE_MASK		},
	{KNOT_VALUE_TYPE_INT, UNIT_CURRENT_MASK		},
	{KNOT_VALUE_TYPE_INT, UNIT_RESISTENCE_MASK	},
	{KNOT_VALUE_TYPE_INT, UNIT_POWER_MASK		},
	{KNOT_VALUE_TYPE_INT, UNIT_TEMP_MASK		},
	{KNOT_VALUE_TYPE_INT, UNIT_HUM_MASK		},
	{KNOT_VALUE_TYPE_INT, UNIT_LUM_MASK		},
	{KNOT_VALUE_TYPE_INT, UNIT_TIME_MASK		},
	{KNOT_VALUE_TYPE_INT, UNIT_MASS_MASK		},
	{KNOT_VALUE_TYPE_INT, UNIT_PRESSURE_MASK	},
	{KNOT_VALUE_TYPE_INT, UNIT_DISTANCE_MASK	},
	{KNOT_VALUE_TYPE_FLOAT, UNIT_ANGLE_MASK		},
	{KNOT_VALUE_TYPE_FLOAT, UNIT_VOL_MASK		},
	{KNOT_VALUE_TYPE_FLOAT, UNIT_AREA_MASK		},
	{KNOT_VALUE_TYPE_FLOAT, UNIT_RAIN_MASK		},
	{KNOT_VALUE_TYPE_FLOAT, UNIT_DENSITY_MASK	},
	{KNOT_VALUE_TYPE_FLOAT, UNIT_LAT_MASK		},
	{KNOT_VALUE_TYPE_FLOAT, UNIT_LONG_MASK		},
	{KNOT_VALUE_TYPE_INT, UNIT_SPEED_MASK		},
	{KNOT_VALUE_TYPE_FLOAT, UNIT_VOLFLOW_MASK	},
	{KNOT_VALUE_TYPE_INT, UNIT_ENERGY_MASK		}
};

static const uint8_t logic_types[]  = {
	KNOT_VALUE_TYPE_BOOL,			// KNOT_TYPE_ID_PRESENCE
	KNOT_VALUE_TYPE_BOOL,			// KNOT_TYPE_ID_SWITCH
	KNOT_VALUE_TYPE_RAW			// KNOT_TYPE_ID_COMMAND
};

static const uint8_t generic_types[] = {
	KNOT_VALUE_TYPE_INT			// KNOT_TYPE_ID_ANALOG
};

int knot_value_type_is_valid(uint8_t type)
{
	if (type >= KNOT_VALUE_TYPE_MIN || type < KNOT_VALUE_TYPE_MAX)
		return KNOT_SUCCESS;

	return KNOT_INVALID_DATA;
}

int knot_type_id_is_basic(uint16_t type_id)
{
	if (type_id < KNOT_TYPE_ID_BASIC_MAX)
		return KNOT_SUCCESS;

	return KNOT_INVALID_DATA;
}

int knot_type_id_is_logic(uint16_t type_id)
{
	if (type_id >= KNOT_TYPE_ID_LOGIC_MIN &&
	    type_id < KNOT_TYPE_ID_LOGIC_MAX)
		return KNOT_SUCCESS;

	return KNOT_INVALID_DATA;
}

int knot_type_id_is_generic(uint16_t type_id)
{
	if (type_id >= KNOT_TYPE_ID_GENERIC_MIN &&
	    type_id < KNOT_TYPE_ID_GENERIC_MAX)
		return KNOT_SUCCESS;

	return KNOT_INVALID_DATA;
}

int knot_schema_is_valid(uint16_t type_id, uint8_t value_type, uint8_t unit)
{
	/* int/float/bool/raw ? */
	if (knot_value_type_is_valid(value_type) == KNOT_SUCCESS) {

		/* Verify basic type IDs */
		if (knot_type_id_is_basic(type_id) == KNOT_SUCCESS) {
			if (basic_types[type_id].value_type == value_type &&
			    basic_types[type_id].unit_mask & UNIT_MASK(unit))
				return KNOT_SUCCESS;

		/* Verify logic type IDs */
		} else if (knot_type_id_is_logic(type_id) == KNOT_SUCCESS) {
			if (logic_types[TYPE_ID_MASK(type_id)] == value_type)
				return KNOT_SUCCESS;
		} else if (knot_type_id_is_generic(type_id) == KNOT_SUCCESS) {
			if (generic_types[TYPE_ID_MASK(type_id)] == value_type)
				return KNOT_SUCCESS;
		}
	}

	return KNOT_INVALID_SCHM;
}

int knot_config_is_valid(uint8_t event_flags, uint8_t value_type,
			 uint16_t time_sec, const knot_value_type *lower_limit,
			 const knot_value_type *upper_limit)
{

	/* Check if event_flags are valid */
	if ((event_flags | KNOT_EVT_FLAG_NONE) &&
		!(event_flags & KNOT_EVENT_FLAG_MAX))
		/*
		 * TODO: DEFINE KNOT_CONFIG ERRORS IN PROTOCOL
		 * KNOT_INVALID_CONFIG in new protocol
		 */
		return KNOT_ERROR_UNKNOWN;

	/* Check consistency of time_sec */
	if (event_flags & KNOT_EVT_FLAG_TIME) {
		if (time_sec == 0)
			/*
			 * TODO: DEFINE KNOT_CONFIG ERRORS IN PROTOCOL
			 * KNOT_INVALID_CONFIG in new protocol
			 */
			return KNOT_ERROR_UNKNOWN;
	} else {
		if (time_sec > 0)
			/*
			 * TODO: DEFINE KNOT_CONFIG ERRORS IN PROTOCOL
			 * KNOT_INVALID_CONFIG in new protocol
			 */
			return KNOT_ERROR_UNKNOWN;
	}

	/* Check consistency of limits */
	if (event_flags & KNOT_EVT_FLAG_LOWER_THRESHOLD &&
			(!lower_limit ||
			value_type == KNOT_VALUE_TYPE_BOOL ||
			value_type == KNOT_VALUE_TYPE_RAW))
		/*
		 * TODO: DEFINE KNOT_CONFIG ERRORS IN PROTOCOL
		 * KNOT_INVALID_CONFIG in new protocol
		 */
		return KNOT_ERROR_UNKNOWN;
	if (event_flags & KNOT_EVT_FLAG_UPPER_THRESHOLD &&
			(!upper_limit ||
			value_type == KNOT_VALUE_TYPE_BOOL ||
			value_type == KNOT_VALUE_TYPE_RAW))
		/*
		 * TODO: DEFINE KNOT_CONFIG ERRORS IN PROTOCOL
		 * KNOT_INVALID_CONFIG in new protocol
		 */
		return KNOT_ERROR_UNKNOWN;

	if ((event_flags & KNOT_EVT_FLAG_LOWER_THRESHOLD) &&
			(event_flags & KNOT_EVT_FLAG_UPPER_THRESHOLD)) {
		/* Event by limits is only available for int and float */
		switch(value_type) {
		case KNOT_VALUE_TYPE_INT:
			if( (upper_limit->val_i - lower_limit->val_i) < 0)
				/*
				 * TODO: DEFINE KNOT_CONFIG ERRORS IN PROTOCOL
				 * KNOT_INVALID_CONFIG in new protocol
				 */
				return KNOT_ERROR_UNKNOWN;
			break;
		case KNOT_VALUE_TYPE_FLOAT:
			if( (upper_limit->val_f - lower_limit->val_f) < 0)
				/*
				 * TODO: DEFINE KNOT_CONFIG ERRORS IN PROTOCOL
				 * KNOT_INVALID_CONFIG in new protocol
				 */
				return KNOT_ERROR_UNKNOWN;
			break;
		default:
			/*
			 * TODO: DEFINE KNOT_CONFIG ERRORS IN PROTOCOL
			 * KNOT_INVALID_CONFIG in new protocol
			 */
			return KNOT_ERROR_UNKNOWN;
		}
	}

	return KNOT_SUCCESS;

}
```

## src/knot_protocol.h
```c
/*
 * Copyright (c) 2015, CESAR.
 * All rights reserved.
 *
 * This software may be modified and distributed under the terms
 * of the BSD license. See the LICENSE file for details.
 *
 */
#include <stdint.h>

#ifndef KNOT_PROTOCOL_H
#define KNOT_PROTOCOL_H

#define KNOT_NO_DATA				2
#define KNOT_DONE				1
#define KNOT_SUCCESS				0
#define KNOT_ERROR_UNKNOWN			-1
#define KNOT_INVALID_DEVICE			-2
#define KNOT_INVALID_DATA			-3
#define KNOT_INVALID_DATA_RAW			-4
#define KNOT_DEVICE_NOT_FOUND			-5
#define KNOT_GW_FAILURE				-6
#define KNOT_CLOUD_FAILURE			-7
#define KNOT_CLOUD_OFFLINE			-8
#define KNOT_INVALID_UUID			-9
#define KNOT_INVALID_UUID_CLOUD			-10
#define KNOT_REGISTER_INVALID_DEVICENAME	-11
#define KNOT_INVALID_SCHEMA			-12
#define KNOT_SCHEMA_NOT_FOUND			-13
#define KNOT_SCHEMA_EMPTY			-14
#define KNOT_INVALID_CREDENTIAL			-15
#define KNOT_CREDENTIAL_UNAUTHORIZED		-16

// Each KNoT Device or user has a unique ID and token as identification
// mechanism
#define KNOT_PROTOCOL_TOKEN_LEN			40
#define KNOT_PROTOCOL_UUID_LEN			36
// A human readable name for each device
#define KNOT_PROTOCOL_DEVICE_NAME_LEN		64
// A human readint8_table name for each data source/sink in the device
#define KNOT_PROTOCOL_DATA_NAME_LEN		64

#define KNOT_PROTOCOL_DATA_ID_MAX		0xFE
#define KNOT_PROTOCOL_DATA_ID_NA		0xFF

#define KNOT_MSG_INVALID			0x00
// KNoT connect/register messages (from device)
#define KNOT_MSG_REGISTER_REQ			0x10
#define KNOT_MSG_REGISTER_RESP			0x11
#define KNOT_MSG_UNREGISTER_REQ			0x12
#define KNOT_MSG_UNREGISTER_RESP		0x13
#define KNOT_MSG_AUTH_REQ			0x14
#define KNOT_MSG_AUTH_RESP			0x15
/*
 * KNoT device config messages (from device)
 * END flag indicates end of schema transfer.
 */
#define KNOT_MSG_SCHEMA				0x40
#define KNOT_MSG_SCHEMA_RESP			0x41
#define KNOT_MSG_SCHEMA_END			0x42
#define KNOT_MSG_SCHEMA_END_RESP		0x43
// KNoT data sending config messages (from gateway)
#define KNOT_MSG_GET_CONFIG			0x50
#define KNOT_MSG_SET_CONFIG			0x51
// KNoT request messages (from gateway)
#define KNOT_MSG_GET_DATA			0x30
#define KNOT_MSG_SET_DATA			0x31
// KNoT response messages (from device)
#define KNOT_MSG_DATA				0x20
#define KNOT_MSG_DATA_RESP			0x21
#define KNOT_MSG_CONFIG				0x24
#define KNOT_MSG_CONFIG_RESP			0x25

// KNoT event flags passed by config messages
#define KNOT_EVT_FLAG_NONE			0x00
#define KNOT_EVT_FLAG_TIME			0x01
#define KNOT_EVT_FLAG_LOWER_THRESHOLD		0x02
#define KNOT_EVT_FLAG_UPPER_THRESHOLD		0x04
#define KNOT_EVT_FLAG_CHANGE			0x08
#define KNOT_EVT_FLAG_UNREGISTERED		0x80
#define KNOT_EVENT_FLAG_MAX			(KNOT_EVT_FLAG_TIME |\
						KNOT_EVT_FLAG_LOWER_THRESHOLD |\
						KNOT_EVT_FLAG_UPPER_THRESHOLD |\
						KNOT_EVT_FLAG_CHANGE)

#define KNOT_DATA_RAW_SIZE			16 // 16 bytes for any command
						   // Can be increased if needed

typedef struct __attribute__ ((packed)) {
	uint8_t			type;
	uint8_t			payload_len;
} knot_msg_header;

typedef struct __attribute__ ((packed)) {
	knot_msg_header		hdr;
	int8_t			result;
} knot_msg_result;

typedef struct __attribute__ ((packed)) {
	knot_msg_header		hdr;
	uint8_t			sensor_id;	// App defined sensor id
} knot_msg_item;

/* Considering the IEEE 754 single-precision floating-point Standard */
typedef float knot_value_type_float;

typedef int32_t knot_value_type_int;

typedef uint8_t knot_value_type_bool;

typedef union __attribute__ ((packed)) {
	knot_value_type_int	val_i;
	knot_value_type_float	val_f;
	knot_value_type_bool	val_b;
	uint8_t			raw[KNOT_DATA_RAW_SIZE];
} knot_value_type;

typedef struct __attribute__ ((packed)) {
	knot_msg_header		hdr;
	uint8_t			sensor_id;	// App defined sensor id
	knot_value_type		payload;
} knot_msg_data;

typedef struct __attribute__ ((packed)) {
	uint8_t			event_flags;
	uint16_t		time_sec;
	knot_value_type		lower_limit;
	knot_value_type		upper_limit;
} knot_config;

typedef struct __attribute__ ((packed)) {
	knot_msg_header		hdr;
	uint8_t			sensor_id;	// App defined sensor id
	knot_config		values;
} knot_msg_config; // hdr + 1 + 37 bytes

typedef struct __attribute__ ((packed)) {
	knot_msg_header		hdr;
	int8_t			result;
	char			uuid[KNOT_PROTOCOL_UUID_LEN];
	char			token[KNOT_PROTOCOL_TOKEN_LEN];
} knot_msg_credential; // hdr + 40 + 36 bytes

typedef struct __attribute__ ((packed)) {
	knot_msg_header		hdr;
	uint64_t		id;	/* Device id: mac or user defined */
	char			devName[KNOT_PROTOCOL_DEVICE_NAME_LEN];
} knot_msg_register; // hdr + 64 bytes

/* Requirement: authenticated PHY link */
typedef struct __attribute__ ((packed)) {
	knot_msg_header		hdr;
} knot_msg_unregister;

typedef struct __attribute__ ((packed)) {
	knot_msg_header		hdr;
	char			uuid[KNOT_PROTOCOL_UUID_LEN];
	char			token[KNOT_PROTOCOL_TOKEN_LEN];
} knot_msg_authentication;

typedef struct __attribute__ ((packed)) {
	uint8_t			value_type;	// KNOT_VALUE_TYPE_* (int, float, bool, raw)
	uint8_t			unit;		// KNOT_UNIT_*
	uint16_t		type_id;	// KNOT_TYPE_ID_*
	char			name[KNOT_PROTOCOL_DATA_NAME_LEN];
} knot_schema; // 69 bytes

typedef struct __attribute__ ((packed)) {
	knot_msg_header		hdr;
	uint8_t			sensor_id;	// App defined sensor id
	knot_schema		values;
} knot_msg_schema;

#define KNOT_MSG_SIZE		(sizeof(knot_msg_header) + sizeof(knot_msg_credential))  // must be greater than max structure size defined above

typedef union __attribute__ ((packed)) {
	knot_msg_header		hdr;
	knot_msg_result		action;
	knot_msg_item		item;
	knot_msg_data		data;
	knot_msg_credential	cred;
	knot_msg_register	reg;
	knot_msg_unregister	unreg;
	knot_msg_authentication	auth;
	knot_msg_schema		schema;
	knot_msg_config		config;
	uint8_t			buffer[KNOT_MSG_SIZE];
} knot_msg;

/*
 * Helper function to validate the value type
 */
int knot_value_type_is_valid(uint8_t type);

/*
 * Helper function to verify if type_id is in basic range
 */
int knot_type_id_is_basic(uint16_t type_id);

/*
 * Helper function to verify if type_id is in logic range
 */
int knot_type_id_is_logic(uint16_t type_id);

/*
 * Helper function to validate the schema
 */
int knot_schema_is_valid(uint16_t type_id, uint8_t value_type, uint8_t unit);

/*
 * Helper function to validate the config
 */
int knot_config_is_valid(uint8_t event_flags, uint8_t value_type,
			 uint16_t time_sec, const knot_value_type *lower_limit,
			 const knot_value_type *upper_limit);


#endif //KNOT_PROTOCOL_H
```

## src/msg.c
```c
/*
 * Copyright (c) 2018, CESAR. All rights reserved.
 *
 * SPDX-License-Identifier: Apache-2.0
 */

#include <zephyr.h>
#include <string.h>

#include <knot/knot_protocol.h>

#include "msg.h"

size_t msg_create_error(knot_msg *msg, uint8_t id, int8_t result)
{
	msg->action.hdr.type = id;
	msg->action.result = result;

	return (sizeof(knot_msg_result) - sizeof(msg->action.hdr));
}

size_t msg_create_reg(knot_msg *msg, uint64_t id,
		      const char *name, size_t name_len)
{
	msg->reg.hdr.type = KNOT_MSG_REG_REQ;
	memcpy(msg->reg.devName, name, name_len);
	msg->reg.hdr.payload_len = name_len + sizeof(msg->reg.id);
	/* TODO: missing endianness */
	msg->reg.id = id;

	return (sizeof(msg->reg.hdr) + msg->reg.hdr.payload_len);
}

size_t msg_create_auth(knot_msg *msg, const char *uuid, const char *token)
{
	strncpy(msg->auth.uuid, uuid, KNOT_PROTOCOL_UUID_LEN);
	strncpy(msg->auth.token, token, KNOT_PROTOCOL_TOKEN_LEN);

	msg->hdr.type = KNOT_MSG_AUTH_REQ;
	msg->hdr.payload_len = KNOT_PROTOCOL_UUID_LEN +
		KNOT_PROTOCOL_TOKEN_LEN;
	return (sizeof(msg->hdr) + msg->hdr.payload_len);
}

size_t msg_create_schema(knot_msg *msg, u8_t id,
		       const knot_schema *schema, bool end)
{
	msg->hdr.type = (end ? KNOT_MSG_SCHM_END_REQ : KNOT_MSG_SCHM_FRAG_REQ);
	msg->schema.sensor_id = id;

	msg->schema.values.value_type = schema->value_type;
	msg->schema.values.unit = schema->unit;
	/* TODO: missing endianess */
	msg->schema.values.type_id = schema->type_id;
	strncpy(msg->schema.values.name, schema->name,
		KNOT_PROTOCOL_DATA_NAME_LEN);

	msg->hdr.payload_len = sizeof(msg->schema.values) +
				sizeof(msg->schema.sensor_id);

	return (sizeof(msg->hdr) + msg->hdr.payload_len);
}

size_t msg_create_data(knot_msg *msg, u8_t id,
		       const knot_value_type *value, uint8_t value_len,
		       bool resp)
{
	msg->hdr.type = resp ? KNOT_MSG_PUSH_DATA_RSP: KNOT_MSG_PUSH_DATA_REQ;
	msg->data.sensor_id = id;

	msg->hdr.payload_len = sizeof(id) + value_len;
	memcpy(&msg->data.payload, value, value_len);

	return (sizeof(msg->hdr) + msg->hdr.payload_len);
}

size_t msg_create_unreg(knot_msg *msg)
{
	msg->hdr.type = KNOT_MSG_UNREG_RSP;
	msg->hdr.payload_len = 0;

	return sizeof(msg->hdr);
}
```
